# MDR1986VK01 register map
File version: 1.0.2
Registers are 32-bit, read-write, no defined reset value unless marked. A register's access mark holds for its fields unless they carry their own. Offsets are from the block's base; [hi:lo] are bit positions.

## MDR_CORDIC — MDR_CORDIC description
Base 0x400B3000
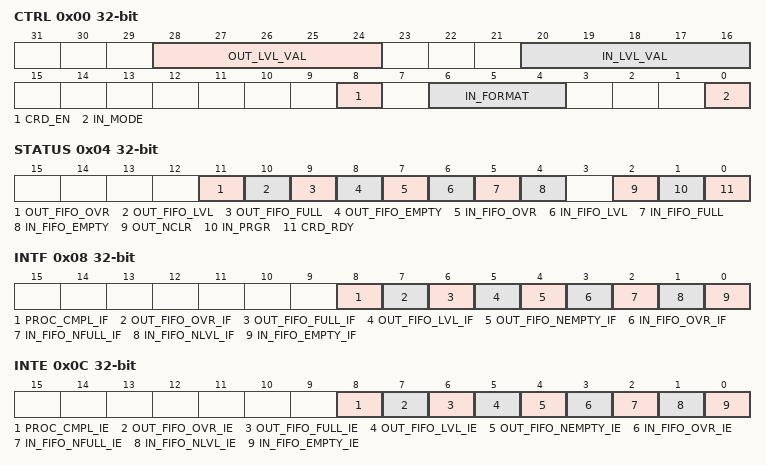
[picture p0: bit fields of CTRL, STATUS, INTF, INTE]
0x00 CTRL — Module control register
  [28:24] OUT_LVL_VAL — The fill level of the output FIFO for generating the OUT_FIFO_LVL signal (see CRD_STATUS status register). Value range [0:31]
  [20:16] IN_LVL_VAL — The fill level of the input FIFO for generating the IN_FIFO_LVL signal (see CRD_STATUS status register). Value range [0:31]
  [8] CRD_EN — Enabling the module: 1 - turn on the module; 0 - turn off the module. Enabling is controlled by bit CRD_RDY (see status register CRD_STATUS)
  [6:4] IN_FORMAT — Working data format: 000 - 32 bit, floating point; 001 - 16 bit, floating point; 010 - 32 bit, integer mode
  [0] IN_MODE — Rotation mode: 0 - Rotate input vector (x;y) by angle alpha. The output is new, rotated vector (x;y), angle alpha is 1 - Rotate input vector (x;y) to the X-axis. The output is the original angle of the vector alpha, and the length of the original vector in the x coordinate (deformed value)
0x04 STATUS — Module status register
  [11] OUT_FIFO_OVR — An attempt was made to read from an empty FIFO. This flag is set to 1 when trying to read data from an empty FIFO when the OUT_FIFO_EMPTY flag is set. The past data will be read from the FIFO, and the flag will be set to 1. The flag is removed upon successful reading from the FIFO, that is, during the next reading from a non-empty FIFO.
  [10] OUT_FIFO_LVL — The output FIFO has more data than the specified amount, this flag is set to 1 when the amount of data stored in the FIFO is greater than OUT_LVL_VAL (see control register CRD_CTRL).
  [9] OUT_FIFO_FULL — The output FIFO is full. This flag is at 1 when the FIFO is full.
  [8] OUT_FIFO_EMPTY — The output FIFO is empty. This flag is set to 1 when the FIFO has no data.
  [7] IN_FIFO_OVR — Input FIFO overflowed. This flag is set to 1 when an attempt is made to write data to a filled FIFO when the IN_FIFO_FULL flag is set. The data written at this moment is discarded, and this flag is set to 1. The flag is removed when a successful write to the FIFO, that is, when the next write to an unfilled FIFO.
  [6] IN_FIFO_LVL — The input FIFO has more data than the specified amount, this flag is set to 1 when the amount of data stored in the FIFO is greater than IN_LVL_VAL (see control register CRD_CTRL)
  [5] IN_FIFO_FULL — The input FIFO is full, this flag is set to 1, when the FIFO is completely full, the data being written when the flag is set is discarded, when trying to write, the IN_FIFO_OVR flag is set
  [4] IN_FIFO_EMPTY — Input FIFO is empty, this flag is set to 1 when there is no data in the input FIFO
  [2] OUT_NCLR — Flag of the presence of uncollected data, this flag is equal to 1 when data is processed in the core of the model or the output FIFO is not empty, at the end of processing and fetching all data from the output FIFO, the flag becomes 0
  [1] IN_PRGR — The flag of the presence of data in processing, this flag is 1 when there is data in the input FIFO or data is being processed in the module core. As soon as the data is processed and the input FIFO is empty, the flag becomes 0
  [0] CRD_RDY — Module readiness for work: 0 - The module is not ready for operation, it is turned off 1 - The module is ready for operation, it is turned on
0x08 INTF — Interrupt flag register
  [8] PROC_CMPL_IF — Data processing is completed, the flag is set when this situation occurs, when the IN_PRGR bit is cleared (see the CRD_STATUS status register), the flag is cleared by writing 1 to this bit
  [7] OUT_FIFO_OVR_IF — Read from an empty FIFO, the flag is set when this situation occurs, when the OUT_FIFO_OVR bit appears (see the CRD_STATUS status register), the flag is cleared by writing 1 to this bit
  [6] OUT_FIFO_FULL_IF — The output FIFO is full, the flag reflects the state of the OUT_FIFO_FULL bit (see the status register CRD_STATUS), is set and removed when the OUT_FIFO_FULL bit appears and clears.
  [5] OUT_FIFO_LVL_IF — The output FIFO is filled above the specified level, the flag reflects the state of the OUT_FIFO_LVL bit (see the status register CRD_STATUS), is set and removed with the appearance and removal of the OUT_FIFO_LVL bit.
  [4] OUT_FIFO_NEMPTY_IF — The output FIFO is not empty, the flag reflects the inverse of the OUT_FIFO_EMPTY bit state (see CRD_STATUS status register). Flag at 1 when OUT_FIFO_EMPTY at 0 and vice versa.
  [3] IN_FIFO_OVR_IF — The input FIFO is overflowed, the flag is set when this situation occurs, when the IN_FIFO_OVR bit appears (see CRS_STATUS status register), the flag is cleared by writing 1 to this bit.
  [2] IN_FIFO_NFULL_IF — The input FIFO is not completely filled, the flag reflects the inverse state of IN_FIFO_FULL bit (see the CRS_STATUS status register). Flag at 1 when IN_FIFO_FULL at 0 and vice versa.
  [1] IN_FIFO_NLVL_IF — The input FIFO is filled no higher than the specified level, the flag reflects the inversion of the state of IN_FIFO_LVL bit (see the CRS_STATUS status register). Flag at 1 when IN_FIFO_LVL at 0 and vice versa.
  [0] IN_FIFO_EMPTY_IF — The input FIFO is empty, the flag reflects the state of IN_FIFO_EMPTY bit (see the CRS_STATUS status register). It is put and removed with the appearance and removal of IN_FIFO_EMPTY bit.
0x0C INTE — Interrupt enable register
  [8] PROC_CMPL_IE — Data processing is completed, the flag is set when this situation occurs, when the IN_PRGR bit is cleared (see the CRD_STATUS status register), the flag is cleared by writing 1 to this bit
  [7] OUT_FIFO_OVR_IE — Read from an empty FIFO, the flag is set when this situation occurs, when the OUT_FIFO_OVR bit appears (see the CRD_STATUS status register), the flag is cleared by writing 1 to this bit
  [6] OUT_FIFO_FULL_IE — The output FIFO is full, the flag reflects the state of the OUT_FIFO_FULL bit (see the status register CRD_STATUS), is set and removed when the OUT_FIFO_FULL bit appears and clears.
  [5] OUT_FIFO_LVL_IE — The output FIFO is filled above the specified level, the flag reflects the state of the OUT_FIFO_LVL bit (see the status register CRD_STATUS), is set and removed with the appearance and removal of the OUT_FIFO_LVL bit.
  [4] OUT_FIFO_NEMPTY_IE — The output FIFO is not empty, the flag reflects the inverse of the OUT_FIFO_EMPTY bit state (see CRD_STATUS status register). Flag at 1 when OUT_FIFO_EMPTY at 0 and vice versa.
  [3] IN_FIFO_OVR_IE — The input FIFO is overflowed, the flag is set when this situation occurs, when the IN_FIFO_OVR bit appears (see CRS_STATUS status register), the flag is cleared by writing 1 to this bit.
  [2] IN_FIFO_NFULL_IE — The input FIFO is not completely filled, the flag reflects the inverse state of IN_FIFO_FULL bit (see the CRS_STATUS status register). Flag at 1 when IN_FIFO_FULL at 0 and vice versa.
  [1] IN_FIFO_NLVL_IE — The input FIFO is filled no higher than the specified level, the flag reflects the inversion of the state of IN_FIFO_LVL bit (see the CRS_STATUS status register). Flag at 1 when IN_FIFO_LVL at 0 and vice versa.
  [0] IN_FIFO_EMPTY_IE — The input FIFO is empty, the flag reflects the state of IN_FIFO_EMPTY bit (see the CRS_STATUS status register). It is put and removed with the appearance and removal of IN_FIFO_EMPTY bit.
0x10 IN_X — Vector X coordinate recording register
0x14 IN_Y — Vector Y coordinate recording register
0x18 IN_A — Register for writing the value of the angle alpha
0x1C IN_SEQ — Sequential write register
0x20 OUT_X — Register for reading the X coordinate of the result vector
0x24 OUT_Y — Register for reading the Y coordinate of the result vector
0x28 OUT_A — alpha angle reading register
0x2C OUT_SEQ — Sequential reading register
0x30 IN_ADDR — Register of record address selection
0x34 OUT_ADDR — Register of read address selection
